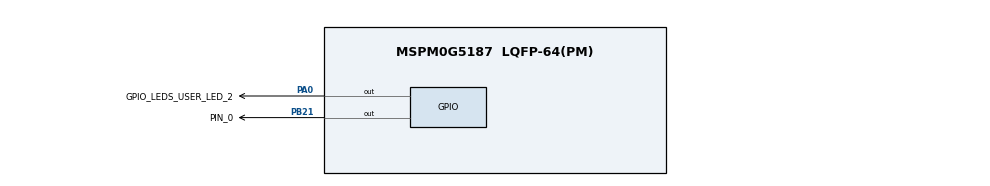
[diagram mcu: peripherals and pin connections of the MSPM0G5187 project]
//@cliArgs --device "MSPM0G518X" --package "LQFP-64(PM)" --part "Default"
//@v2CliArgs --device "MSPM0G5187" --package "LQFP-64(PM)"
// @cliArgs --board /ti/boards/LP_MSPM0G5187 --rtos nortos

/**
 * Import the modules used in this configuration.
 */
const ADC12         = scripting.addModule("/ti/driverlib/ADC12", {}, false);
const ADC121        = ADC12.addInstance();
const GPIO          = scripting.addModule("/ti/driverlib/GPIO", {}, false);
const GPIO1         = GPIO.addInstance();
const GPIO2         = GPIO.addInstance();
const GPIO3         = GPIO.addInstance();
const SYSCTL        = scripting.addModule("/ti/driverlib/SYSCTL");
const TIMER         = scripting.addModule("/ti/driverlib/TIMER", {}, false);
const TIMER1        = TIMER.addInstance();
const ProjectConfig = scripting.addModule("/ti/project_config/ProjectConfig");

/**
 * Write custom configuration values to the imported modules.
 */
const divider9       = system.clockTree["UDIV"];
divider9.divideValue = 2;

const multiplier2         = system.clockTree["PLL_QDIV"];
multiplier2.multiplyValue = 5;

const mux4       = system.clockTree["EXLFMUX"];
mux4.inputSelect = "EXLFMUX_XTAL";

const mux7       = system.clockTree["HSCLKMUX"];
mux7.inputSelect = "HSCLKMUX_SYSPLL0";

ADC121.$name                       = "ADC12_0";
ADC121.adcMem0chansel              = "DL_ADC12_INPUT_CHAN_24";
ADC121.sampClkSrc                  = "DL_ADC12_CLOCK_ULPCLK";
ADC121.trigSrc                     = "DL_ADC12_TRIG_SRC_EVENT";
ADC121.repeatMode                  = true;
ADC121.adcMem0avgen                = true;
ADC121.hwNumerator                 = "DL_ADC12_HW_AVG_NUM_ACC_8";
ADC121.adcMem0trig                 = "DL_ADC12_TRIGGER_MODE_TRIGGER_NEXT";
ADC121.hwDenominator               = "DL_ADC12_HW_AVG_DEN_DIV_BY_2";
ADC121.subChanID                   = 1;
ADC121.enabledEvents               = ["DL_ADC12_EVENT_MEM0_RESULT_LOADED"];
ADC121.enabledInterrupts           = ["DL_ADC12_INTERRUPT_MEM0_RESULT_LOADED","DL_ADC12_INTERRUPT_TRIG_OVF"];
ADC121.powerDownMode               = "DL_ADC12_POWER_DOWN_MODE_MANUAL";
ADC121.peripheral.$assign          = "ADC0";
ADC121.peripheral.adcPin24.$assign = "PB22";

const Board = scripting.addModule("/ti/driverlib/Board", {}, false);

GPIO1.$name                   = "GPIO_LEDS";
GPIO1.port                    = "PORTB";
GPIO1.associatedPins[0].$name = "LED_1";

GPIO2.$name                         = "GPIO_LED2";
GPIO2.associatedPins[0].$name       = "GPIO_LEDS_USER_LED_2";
GPIO2.associatedPins[0].pin.$assign = "PA0";

GPIO3.port                           = "PORTB";
GPIO3.$name                          = "GPIO_GRP_0";
GPIO3.associatedPins[0].initialValue = "SET";
GPIO3.associatedPins[0].$name        = "PIN_0";
GPIO3.associatedPins[0].pin.$assign  = "PB21";

SYSCTL.forceDefaultClkConfig = true;
SYSCTL.clockTreeEn           = true;

TIMER1.$name                       = "TIMER_0";
TIMER1.timerClkSrc                 = "LFCLK";
TIMER1.timerMode                   = "PERIODIC";
TIMER1.counterZero                 = true;
TIMER1.event1PublisherChannel      = 1;
TIMER1.event1ControllerInterruptEn = ["ZERO_EVENT"];
TIMER1.timerClkDiv                 = 2;
TIMER1.timerPeriod                 = "0.1 ms";
TIMER1.timerStartTimer             = true;
TIMER1.peripheral.$assign          = "TIMG0";

ProjectConfig.genLibNPU = true;
